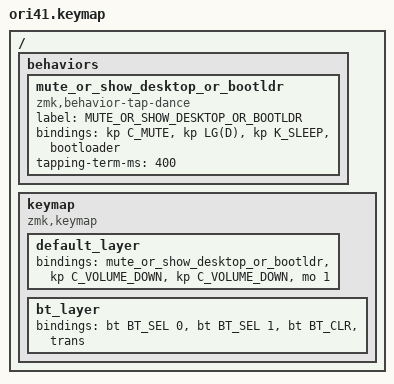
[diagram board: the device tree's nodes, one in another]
/*
 * Copyright (c) 2022 The ZMK Contributors
 *
 * SPDX-License-Identifier: MIT
 */

#include <behaviors.dtsi>
#include <dt-bindings/zmk/bt.h>
#include <dt-bindings/zmk/keys.h>

/ {
    behaviors {
        mute_or_show_desktop_or_bootldr: mute_or_show_desktop_or_bootldr {
            compatible = "zmk,behavior-tap-dance";
            label = "MUTE_OR_SHOW_DESKTOP_OR_BOOTLDR";
            #binding-cells = <0>;
            bindings = <&kp C_MUTE>, <&kp LG(D)>, <&kp K_SLEEP>, <&bootloader>;

            tapping-term-ms = <400>;
        };
    };

    keymap {
        compatible = "zmk,keymap";

        default_layer {
            bindings = <
&mute_or_show_desktop_or_bootldr  &kp C_VOLUME_DOWN  &kp C_VOLUME_DOWN  &mo 1
            >;
        };

        bt_layer {
            bindings = <
&bt BT_SEL 0  &bt BT_SEL 1  &bt BT_CLR  &trans
            >;
        };
    };
};
